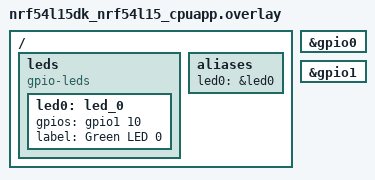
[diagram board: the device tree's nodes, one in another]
/* app.overlay - 自定义LED和按键引脚配置 */

/ {
    leds {
        compatible = "gpio-leds";
        
        led0: led_0 {
            gpios = <&gpio1 10 GPIO_ACTIVE_HIGH>;   // 修改为你的LED0引脚 P1.10
            label = "Green LED 0";
        };
        
        /* led1: led_1 {
            gpios = <&gpio1 6 GPIO_ACTIVE_HIGH>;   // 修改为你的LED1引脚 P1.06
            label = "Green LED 1";
        };
        
        led2: led_2 {
            gpios = <&gpio1 7 GPIO_ACTIVE_HIGH>;   // 修改为你的LED2引脚 P1.07
            label = "Green LED 2";
        };
        
        led3: led_3 {
            gpios = <&gpio1 8 GPIO_ACTIVE_HIGH>;   // 修改为你的LED3引脚 P1.08
            label = "Green LED 3";
        }; */
    };
    
   /*  buttons {
        compatible = "gpio-keys";
        
        button0: button_0 {
            gpios = <&gpio0 10 (GPIO_PULL_UP | GPIO_ACTIVE_LOW)>;  // P0.10
            label = "Push button 0";
            zephyr,code = <INPUT_KEY_0>;
        };
        
        button1: button_1 {
            gpios = <&gpio0 11 (GPIO_PULL_UP | GPIO_ACTIVE_LOW)>;  // P0.11
            label = "Push button 1";
            zephyr,code = <INPUT_KEY_1>;
        };
        
        button2: button_2 {
            gpios = <&gpio0 12 (GPIO_PULL_UP | GPIO_ACTIVE_LOW)>;  // P0.12
            label = "Push button 2";
            zephyr,code = <INPUT_KEY_2>;
        };
        
        button3: button_3 {
            gpios = <&gpio0 13 (GPIO_PULL_UP | GPIO_ACTIVE_LOW)>;  // P0.13
            label = "Push button 3";
            zephyr,code = <INPUT_KEY_3>;
        };
    }; */

    aliases {
        led0 = &led0;
      /*   led1 = &led1;
        led2 = &led2;
        led3 = &led3;
        sw0 = &button0;
        sw1 = &button1;
        sw2 = &button2;
        sw3 = &button3; */
    };
};

/* 确保需要的GPIO端口被启用 */
&gpio0 {
    status = "okay";
};

&gpio1 {
    status = "okay";
};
